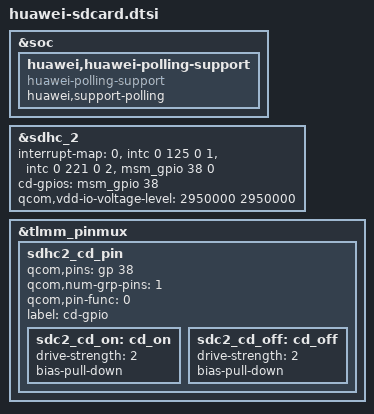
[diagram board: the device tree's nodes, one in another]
/* gpio_active_high */
&soc {
        huawei,huawei-polling-support {
                compatible = "huawei-polling-support";
                huawei,support-polling;
        };
     };

&sdhc_2 {
        interrupt-map = <0 &intc 0 125 0
                1 &intc 0 221 0
                2 &msm_gpio 38 0>;
        cd-gpios = <&msm_gpio 38 0x0>;
        /delete-property/ qcom,vdd-always-on;
        /delete-property/ qcom,vdd-io-always-on;
        /* As the limit of hardware, remove the support of uhs */
        qcom,vdd-io-voltage-level = <2950000 2950000>;
};

&tlmm_pinmux {
        sdhc2_cd_pin {
                qcom,pins = <&gp 38>;
                qcom,num-grp-pins = <1>;
                qcom,pin-func = <0>;
                label = "cd-gpio";
                sdc2_cd_on: cd_on {
                        drive-strength = <2>;
                        /delete-property/ bias-pull-up;
                        /delete-property/ bias-disable;
                        bias-pull-down;
                };
                sdc2_cd_off: cd_off {
                        drive-strength = <2>;
                        /delete-property/ bias-pull-up;
                        /delete-property/ bias-disable;
                        bias-pull-down;
                };
        };

};
